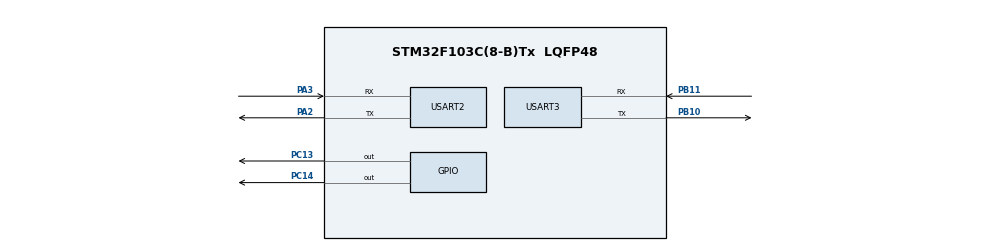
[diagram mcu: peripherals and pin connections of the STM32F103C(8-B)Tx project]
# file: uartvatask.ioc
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FREERTOS.Queues01=myQueue01,16,uint16_t,0,Dynamic,NULL,NULL
FREERTOS.Tasks01=defaultTask,0,128,StartDefaultTask,Default,NULL,Dynamic,NULL,NULL
Mcu.Family=STM32F1
Mcu.Name=STM32F103C(8-B)Tx
Mcu.Package=LQFP48
NVIC.PriorityGroup=NVIC_PRIORITYGROUP_4
NVIC.TIM4_IRQn=true\:15\:0\:false\:false\:true\:false\:false\:true\:true
NVIC.TimeBase=TIM4_IRQn
NVIC.TimeBaseIP=TIM4
NVIC.USART2_IRQn=true\:5\:0\:false\:false\:true\:true\:true\:true\:true
NVIC.USART3_IRQn=true\:5\:0\:false\:false\:true\:true\:true\:true\:true
PA0-WKUP.Mode=SYS_WakeUp0
PA0-WKUP.Signal=SYS_WKUP
PA13.Mode=Serial_Wire
PA13.Signal=SYS_JTMS-SWDIO
PA14.Mode=Serial_Wire
PA14.Signal=SYS_JTCK-SWCLK
PA2.Mode=Asynchronous
PA2.Signal=USART2_TX
PA3.Mode=Asynchronous
PA3.Signal=USART2_RX
PB10.Mode=Asynchronous
PB10.Signal=USART3_TX
PB11.Mode=Asynchronous
PB11.Signal=USART3_RX
PC13-TAMPER-RTC.Signal=GPIO_Output
PC14-OSC32_IN.Signal=GPIO_Output
ProjectManager.HeapSize=0x200
ProjectManager.StackSize=0x400
ProjectManager.TargetToolchain=MDK-ARM V5.32
RCC.APB1Freq_Value=8000000
RCC.APB2Freq_Value=8000000
USART2.VirtualMode=VM_ASYNC
USART3.VirtualMode=VM_ASYNC
VP_FREERTOS_VS_CMSIS_V1.Mode=CMSIS_V1
VP_SYS_VS_tim4.Mode=TIM4
board=custom

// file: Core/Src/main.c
/* USER CODE BEGIN Header */
/**
  ******************************************************************************
  * @file           : main.c
  * @brief          : Main program body
  ******************************************************************************
  * @attention
  *
  * Copyright (c) 2023 STMicroelectronics.
  * All rights reserved.
  *
  * This software is licensed under terms that can be found in the LICENSE file
  * in the root directory of this software component.
  * If no LICENSE file comes with this software, it is provided AS-IS.
  *
  ******************************************************************************
  */
/* USER CODE END Header */
#include "main.h"
#include "cmsis_os.h"
//#include "stm32f10x.h"                  // Device header
#include "response_ci.h"

UART_HandleTypeDef huart2;
UART_HandleTypeDef huart3;

osThreadId defaultTaskHandle;
osMessageQId myQueue01Handle;
osThreadId AboveNormalHandle;
osThreadId BlinkLedNormalHandle;
osThreadId BlinkLedRecivedataHandle;

void SystemClock_Config(void);
static void MX_GPIO_Init(void);
static void MX_USART2_UART_Init(void);
static void MX_USART3_UART_Init(void);
void StartDefaultTask(void const * argument);
void AboveNormalTask(void const *pragmeter);
void BlinkLedNormalTask(void const * argument);
void BlinkLedRecivedataTask(void const * argument);

int main(void)
{

  /* MCU Configuration--------------------------------------------------------*/

  /* Reset of all peripherals, Initializes the Flash interface and the Systick. */
  HAL_Init();

  /* Configure the system clock */
  SystemClock_Config();

  /* Initialize all configured peripherals */
  MX_GPIO_Init();
  MX_USART2_UART_Init();
  MX_USART3_UART_Init();
	response_init2(&huart2);

  /* Create the queue(s) */
  /* definition and creation of myQueue01 */
  osMessageQDef(myQueue01, 16, uint16_t);
  myQueue01Handle = osMessageCreate(osMessageQ(myQueue01), NULL);

  /* Create the thread(s) */
  /* definition and creation of defaultTask */
  osThreadDef(defaultTask, StartDefaultTask, osPriorityNormal, 0, 128);
  defaultTaskHandle = osThreadCreate(osThread(defaultTask), NULL);
	 	osThreadDef(Task1,AboveNormalTask,osPriorityAboveNormal,0,128);//MUON SU DUNG TASK THI PHAI KHAI BAO THE NEN MOI CO DOG NAY, CAC THONG
	// SO TRUYEN VAO LAN LUOT LA:TEN,HAM CUA TASK DA KHAI BAO ,MUC UU TIEN,SO PHIEN BAN CUA TASK , KICH THUOC
	AboveNormalHandle=osThreadCreate(osThread(Task1),NULL);

osThreadDef(Task3,BlinkLedNormalTask,osPriorityHigh,0,128);
BlinkLedNormalHandle=osThreadCreate(osThread(Task3),NULL);
  /* USER CODE BHREADS */
	osThreadDef(Task4,BlinkLedRecivedataTask,osPriorityBelowNormal,0,128);
BlinkLedNormalHandle=osThreadCreate(osThread(Task4),NULL);
  /* add threads, ... */
  /* USER CODE END RTOS_THREADS */

  /* Start scheduler */
  osKernelStart();

  /* We should never get here as control is now taken by the scheduler */
  /* Infinite loop */
  while (1)
  {

  }
}

void SystemClock_Config(void)
{
  RCC_OscInitTypeDef RCC_OscInitStruct = {0};
  RCC_ClkInitTypeDef RCC_ClkInitStruct = {0};

  /** Initializes the RCC Oscillators according to the specified parameters
  * in the RCC_OscInitTypeDef structure.
  */
  RCC_OscInitStruct.OscillatorType = RCC_OSCILLATORTYPE_HSI;
  RCC_OscInitStruct.HSIState = RCC_HSI_ON;
  RCC_OscInitStruct.HSICalibrationValue = RCC_HSICALIBRATION_DEFAULT;
  RCC_OscInitStruct.PLL.PLLState = RCC_PLL_NONE;
  if (HAL_RCC_OscConfig(&RCC_OscInitStruct) != HAL_OK)
  {
    Error_Handler();
  }

  /** Initializes the CPU, AHB and APB buses clocks
  */
  RCC_ClkInitStruct.ClockType = RCC_CLOCKTYPE_HCLK|RCC_CLOCKTYPE_SYSCLK
                              |RCC_CLOCKTYPE_PCLK1|RCC_CLOCKTYPE_PCLK2;
  RCC_ClkInitStruct.SYSCLKSource = RCC_SYSCLKSOURCE_HSI;
  RCC_ClkInitStruct.AHBCLKDivider = RCC_SYSCLK_DIV1;
  RCC_ClkInitStruct.APB1CLKDivider = RCC_HCLK_DIV1;
  RCC_ClkInitStruct.APB2CLKDivider = RCC_HCLK_DIV1;

  if (HAL_RCC_ClockConfig(&RCC_ClkInitStruct, FLASH_LATENCY_0) != HAL_OK)
  {
    Error_Handler();
  }
}

static void MX_USART2_UART_Init(void)
{

  huart2.Instance = USART2;
  huart2.Init.BaudRate = 115200;
  huart2.Init.WordLength = UART_WORDLENGTH_8B;
  huart2.Init.StopBits = UART_STOPBITS_1;
  huart2.Init.Parity = UART_PARITY_NONE;
  huart2.Init.Mode = UART_MODE_TX_RX;
  huart2.Init.HwFlowCtl = UART_HWCONTROL_NONE;
  huart2.Init.OverSampling = UART_OVERSAMPLING_16;
  if (HAL_UART_Init(&huart2) != HAL_OK)
  {
    Error_Handler();
  }

}

static void MX_USART3_UART_Init(void)
{

  huart3.Instance = USART3;
  huart3.Init.BaudRate = 115200;
  huart3.Init.WordLength = UART_WORDLENGTH_8B;
  huart3.Init.StopBits = UART_STOPBITS_1;
  huart3.Init.Parity = UART_PARITY_NONE;
  huart3.Init.Mode = UART_MODE_TX_RX;
  huart3.Init.HwFlowCtl = UART_HWCONTROL_NONE;
  huart3.Init.OverSampling = UART_OVERSAMPLING_16;
  if (HAL_UART_Init(&huart3) != HAL_OK)
  {
    Error_Handler();
  }

}

static void MX_GPIO_Init(void)
{
  GPIO_InitTypeDef GPIO_InitStruct = {0};

  /* GPIO Ports Clock Enable */
  __HAL_RCC_GPIOC_CLK_ENABLE();
  __HAL_RCC_GPIOA_CLK_ENABLE();
  __HAL_RCC_GPIOB_CLK_ENABLE();

  /*Configure GPIO pin Output Level */
  HAL_GPIO_WritePin(GPIOC, GPIO_PIN_13|GPIO_PIN_14, GPIO_PIN_RESET);

  /*Configure GPIO pins : PC13 PC14 */
  GPIO_InitStruct.Pin = GPIO_PIN_13|GPIO_PIN_14;
  GPIO_InitStruct.Mode = GPIO_MODE_OUTPUT_PP;
  GPIO_InitStruct.Pull = GPIO_NOPULL;
  GPIO_InitStruct.Speed = GPIO_SPEED_FREQ_LOW;
  HAL_GPIO_Init(GPIOC, &GPIO_InitStruct);

}

void Blinkled_Normal(){
HAL_GPIO_TogglePin(GPIOC,GPIO_PIN_13);
response_print2("\n led13_on ");
}
void BlinkLed_Senddata(int a){
//HAL_GPIO_WritePin(GPIOC,GPIO_PIN_14,a);
response_print2("\n led14_on ");
}
void StartDefaultTask(void const * argument)
{
  /* USER CODE BEGIN 5 */
  /* Infinite loop */
  for(;;)
  {
		osEvent Recv_Task_data;
			Recv_Task_data=osMessageGet(myQueue01Handle,osWaitForever);
		response_print2("\n this is Sever_task ");
		response_print2("%d",Recv_Task_data.value.v);
		if(Recv_Task_data.value.v>100){
				response_print2("\n error");
		}
		else{
		   				response_print2("\n true");

		}
    osDelay(500);
  }
  /* USER CODE END 5 */
}
void AboveNormalTask(void const *pragmeter){
while(1){
		response_print2("\n this is Client_task ");
	uint32_t task_data =20;
	osMessagePut(myQueue01Handle,task_data,10);
	osDelay(1000);//trong rtos thi su dung ham nay de chay delay
}
}
void BlinkLedNormalTask(void const * argument){
response_print2("\n this is blinknormal ");
	Blinkled_Normal();
	osDelay(6000);
}
void BlinkLedRecivedataTask(void const * argument){
BlinkLed_Senddata(1);
		osDelay(7000);
}
void HAL_TIM_PeriodElapsedCallback(TIM_HandleTypeDef *htim)
{
  if (htim->Instance == TIM4) {
    HAL_IncTick();
  }
}

void Error_Handler(void)
{
  __disable_irq();
  while (1)
  {
  }
}
